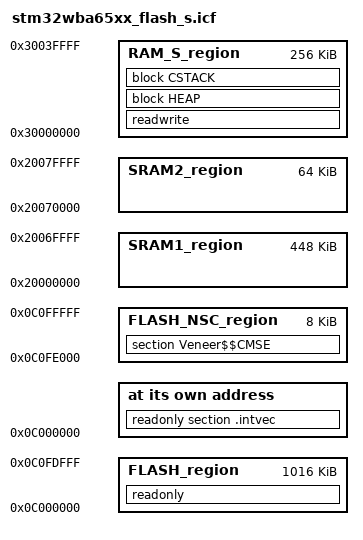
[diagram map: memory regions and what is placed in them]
/**********************************************************************************/
/**** Linker File (ICF)                                                        ****/
/**********************************************************************************/

/*-Symbols-*/
define symbol __region_FLASH_start__       = 0x0C000000;
define symbol __region_FLASH_end__         = 0x0C0FDFFF;

define symbol __region_FLASH_NSC_start__   = 0x0C0FE000;
define symbol __region_FLASH_NSC_end__     = 0x0C0FFFFF;

define symbol __region_FLASH_NS_start__    = 0x08100000;
define symbol __region_FLASH_NS_end__      = 0x081FFFFF;

define symbol __region_SRAM1_start__       = 0x20000000;
define symbol __region_SRAM1_end__         = 0x2006FFFF;
define symbol __region_SRAM2_start__       = 0x20070000;
define symbol __region_SRAM2_end__         = 0x2007FFFF;
define symbol __region_RAM_S_start__       = 0x30000000;
define symbol __region_RAM_S_end__         = 0x3003FFFF;

define symbol __size_heap__                = 0x0000;
define symbol __size_cstack__              = 0x1000;
define symbol __intvec_start__             = __region_FLASH_start__;

/*-Memory Regions-*/
define memory mem with size = 4G;
define region FLASH_region    = mem:[from __region_FLASH_start__ to __region_FLASH_end__];
define region FLASH_NSC_region = mem:[from __region_FLASH_NSC_start__ to __region_FLASH_NSC_end__];
define region SRAM1_region    = mem:[from __region_SRAM1_start__ to __region_SRAM1_end__];
define region SRAM2_region    = mem:[from __region_SRAM2_start__ to __region_SRAM2_end__];
define region SRAM_region     = SRAM1_region | SRAM2_region;
define region RAM_S_region    = mem:[from __region_RAM_S_start__ to __region_RAM_S_end__];

/*-Blocks-*/
define block HEAP      with alignment = 8, size = __size_heap__   { };
define block CSTACK    with alignment = 8, size = __size_cstack__ { };

/*-Initialization strategies-*/
initialize by copy { readwrite };
do not initialize  { section .noinit };

/*-Sections placements-*/
place at address mem:__intvec_start__ { readonly section .intvec };

place in FLASH_region       { readonly };

place in FLASH_NSC_region   { section Veneer$$CMSE };
place in SRAM1_region       { };
place in SRAM2_region       { };
place in SRAM_region        { };
place in RAM_S_region       { readwrite, block HEAP, block CSTACK };
